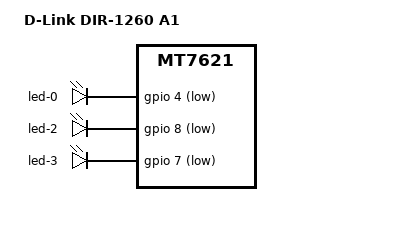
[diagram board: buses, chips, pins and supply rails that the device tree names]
// SPDX-License-Identifier: GPL-2.0-or-later OR MIT

#include "mt7621_dlink_dir_nand_128m.dtsi"

/ {
	compatible = "dlink,dir-1260-a1", "mediatek,mt7621-soc";
	model = "D-Link DIR-1260 A1";
};

&wps {
	gpios = <&gpio 14 GPIO_ACTIVE_LOW>;
};

&leds {
	led-0 {
		gpios = <&gpio 4 GPIO_ACTIVE_LOW>;
	};

	led-2 {
		gpios = <&gpio 8 GPIO_ACTIVE_LOW>;
	};

	led-3 {
		gpios = <&gpio 7 GPIO_ACTIVE_LOW>;
	};
};
